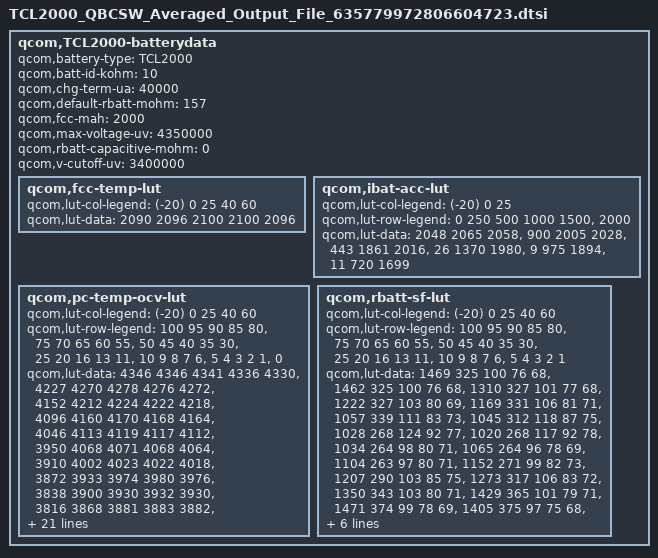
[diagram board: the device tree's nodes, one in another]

qcom,TCL2000-batterydata {
	qcom,battery-type = "TCL2000";
	qcom,batt-id-kohm = <10>;
	qcom,chg-term-ua = <40000>;
	qcom,default-rbatt-mohm = <157>;
	qcom,fcc-mah = <2000>;
	qcom,max-voltage-uv = <4350000>;
	qcom,rbatt-capacitive-mohm = <0>;
	qcom,v-cutoff-uv = <3400000>;

	qcom,fcc-temp-lut {
		qcom,lut-col-legend = <(-20) 0 25 40 60>;
		qcom,lut-data = <2090 2096 2100 2100 2096>;
	};

	qcom,ibat-acc-lut {
		qcom,lut-col-legend = <(-20) 0 25>;
		qcom,lut-row-legend = <0 250 500 1000 1500>,
					<2000>;
		qcom,lut-data = <2048 2065 2058>,
				<900 2005 2028>,
				<443 1861 2016>,
				<26 1370 1980>,
				<9 975 1894>,
				<11 720 1699>;
	};

	qcom,pc-temp-ocv-lut {
		qcom,lut-col-legend = <(-20) 0 25 40 60>;
		qcom,lut-row-legend = <100 95 90 85 80>,
					<75 70 65 60 55>,
					<50 45 40 35 30>,
					<25 20 16 13 11>,
					<10 9 8 7 6>,
					<5 4 3 2 1>,
					<0>;
		qcom,lut-data = <4346 4346 4341 4336 4330>,
				<4227 4270 4278 4276 4272>,
				<4152 4212 4224 4222 4218>,
				<4096 4160 4170 4168 4164>,
				<4046 4113 4119 4117 4112>,
				<3950 4068 4071 4068 4064>,
				<3910 4002 4023 4022 4018>,
				<3872 3933 3974 3980 3976>,
				<3838 3900 3930 3932 3930>,
				<3816 3868 3881 3883 3882>,
				<3799 3840 3850 3851 3850>,
				<3784 3814 3826 3827 3826>,
				<3770 3796 3806 3808 3806>,
				<3758 3786 3790 3790 3788>,
				<3746 3776 3776 3772 3764>,
				<3734 3762 3762 3753 3740>,
				<3721 3740 3740 3730 3717>,
				<3708 3715 3710 3702 3688>,
				<3694 3702 3691 3683 3671>,
				<3684 3696 3689 3681 3670>,
				<3676 3694 3688 3680 3669>,
				<3668 3692 3686 3679 3668>,
				<3658 3690 3686 3678 3666>,
				<3646 3687 3684 3676 3664>,
				<3630 3680 3676 3668 3654>,
				<3608 3662 3654 3643 3618>,
				<3575 3620 3604 3592 3567>,
				<3524 3560 3539 3528 3502>,
				<3442 3474 3450 3438 3406>,
				<3296 3326 3294 3280 3253>,
				<3038 3000 3000 3000 3000>;
	};

	qcom,rbatt-sf-lut {
		qcom,lut-col-legend = <(-20) 0 25 40 60>;
		qcom,lut-row-legend = <100 95 90 85 80>,
					<75 70 65 60 55>,
					<50 45 40 35 30>,
					<25 20 16 13 11>,
					<10 9 8 7 6>,
					<5 4 3 2 1>;
		qcom,lut-data = <1469 325 100 76 68>,
				<1462 325 100 76 68>,
				<1310 327 101 77 68>,
				<1222 327 103 80 69>,
				<1169 331 106 81 71>,
				<1057 339 111 83 73>,
				<1045 312 118 87 75>,
				<1028 268 124 92 77>,
				<1020 268 117 92 78>,
				<1034 264 98 80 71>,
				<1065 264 96 78 69>,
				<1104 263 97 80 71>,
				<1152 271 99 82 73>,
				<1207 290 103 85 75>,
				<1273 317 106 83 72>,
				<1350 343 103 80 71>,
				<1429 365 101 79 71>,
				<1471 374 99 78 69>,
				<1405 375 97 75 68>,
				<1462 398 101 78 69>,
				<1491 410 103 79 70>,
				<1524 427 106 82 74>,
				<1595 447 110 85 77>,
				<1709 467 113 87 82>,
				<1841 487 117 90 80>,
				<2013 500 113 85 72>,
				<2241 506 111 83 74>,
				<2611 532 118 88 78>,
				<3254 575 130 96 85>,
				<5485 1149 260 181 171>;
	};
};
/* TEST_DB_ID=TEST_ID_NOT_SET */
